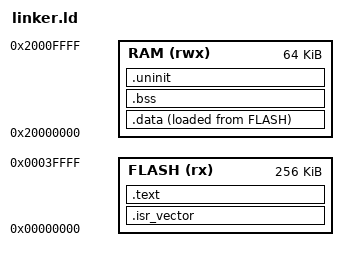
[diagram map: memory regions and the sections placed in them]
/*
 *
 * Assumptions for the first boot target:
 * - code executes from FLASH at 0x00000000
 * - RAM starts at 0x20000000
 * - vector table is placed at the start of FLASH
 *
 * This layout matches common Cortex-M3 QEMU setups such as lm3s6965evb.
 */

ENTRY(Reset_Handler)

MEMORY
{
    FLASH (rx)  : ORIGIN = 0x00000000, LENGTH = 256K
    RAM   (rwx) : ORIGIN = 0x20000000, LENGTH = 64K
}

_estack = ORIGIN(RAM) + LENGTH(RAM);

SECTIONS
{
    .isr_vector : ALIGN(4)
    {
        KEEP(*(.isr_vector))
    } > FLASH

    .text : ALIGN(4)
    {
        *(.text .text.*)
        *(.rodata .rodata.*)
        *(.glue_7)
        *(.glue_7t)
        *(.eh_frame)
        . = ALIGN(4);
    } > FLASH

    /*
     * _sidata points at the flash image for initialized data.
     * The reset handler copies this range into .data in RAM.
     */
    _sidata = LOADADDR(.data);

    .data : ALIGN(4)
    {
        _sdata = .;
        *(.data .data.*)
        . = ALIGN(4);
        _edata = .;
    } > RAM AT > FLASH

    .bss (NOLOAD) : ALIGN(4)
    {
        _sbss = .;
        *(.bss .bss.*)
        *(COMMON)
        . = ALIGN(4);
        _ebss = .;
    } > RAM

    .uninit (NOLOAD) : ALIGN(4)
    {
        *(.uninit .uninit.*)
        . = ALIGN(4);
    } > RAM

    /DISCARD/ :
    {
        *(.comment)
        *(.note*)
    }
}
